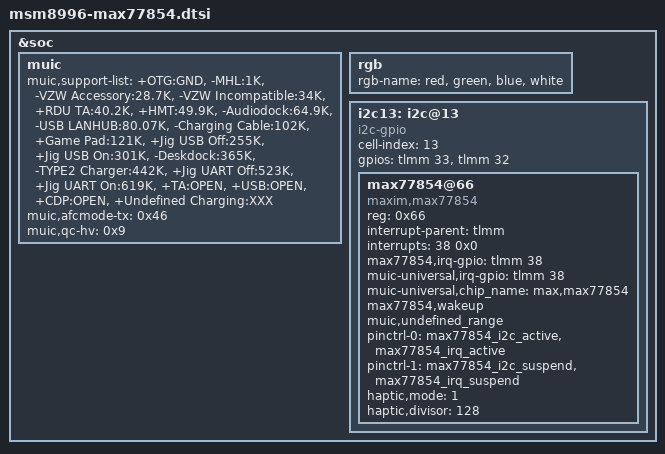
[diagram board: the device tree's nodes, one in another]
/* Copyright (c) 2012, The Linux Foundation. All rights reserved.
 *
 * This program is free software; you can redistribute it and/or modify
 * it under the terms of the GNU General Public License version 2 and
 * only version 2 as published by the Free Software Foundation.
 *
 * This program is distributed in the hope that it will be useful,
 * but WITHOUT ANY WARRANTY; without even the implied warranty of
 * MERCHANTABILITY or FITNESS FOR A PARTICULAR PURPOSE.  See the
 * GNU General Public License for more details.
 */

&soc {
        muic {
                status = "okay";
		muic,support-list = "+OTG:GND",
				"-MHL:1K",
				"-VZW Accessory:28.7K",
				"-VZW Incompatible:34K",
				"+RDU TA:40.2K",
				"+HMT:49.9K",
				"-Audiodock:64.9K",
				"-USB LANHUB:80.07K",
				"-Charging Cable:102K",
				"+Game Pad:121K",
				"+Jig USB Off:255K",
				"+Jig USB On:301K",
				"-Deskdock:365K",
				"-TYPE2 Charger:442K",
				"+Jig UART Off:523K",
				"+Jig UART On:619K",
				"+TA:OPEN",
				"+USB:OPEN",
				"+CDP:OPEN",
				"+Undefined Charging:XXX";
                muic,afcmode-tx = /bits/ 8 <0x46>;
		muic,qc-hv = /bits/ 8 <0x9>;
	};

	rgb {
		rgb-name = "red", "green", "blue", "white";
	};

	i2c13: i2c@13 {
		cell-index = <13>;
		compatible = "i2c-gpio";
		gpios = <&tlmm 33 0 /* sda */
			&tlmm 32 0 /* scl */
			>;
		#address-cells = <1>;
		#size-cells = <0>;

		max77854@66 {
			compatible = "maxim,max77854";
			reg = <0x66>;
			interrupt-parent = <&tlmm>;
			interrupts = <38 0x0>;
			max77854,irq-gpio = <&tlmm 38 0x00>;
			muic-universal,irq-gpio = <&tlmm 38 0x00>;
			muic-universal,chip_name = "max,max77854";
			max77854,wakeup;
			muic,undefined_range;
			pinctrl-names = "max77854_active", "max77854_suspend";
			pinctrl-0 = <&max77854_i2c_active &max77854_irq_active>;
			pinctrl-1 = <&max77854_i2c_suspend &max77854_irq_suspend>;
			haptic,mode = <1>;
			haptic,divisor = <128>;
		};
	};
};

